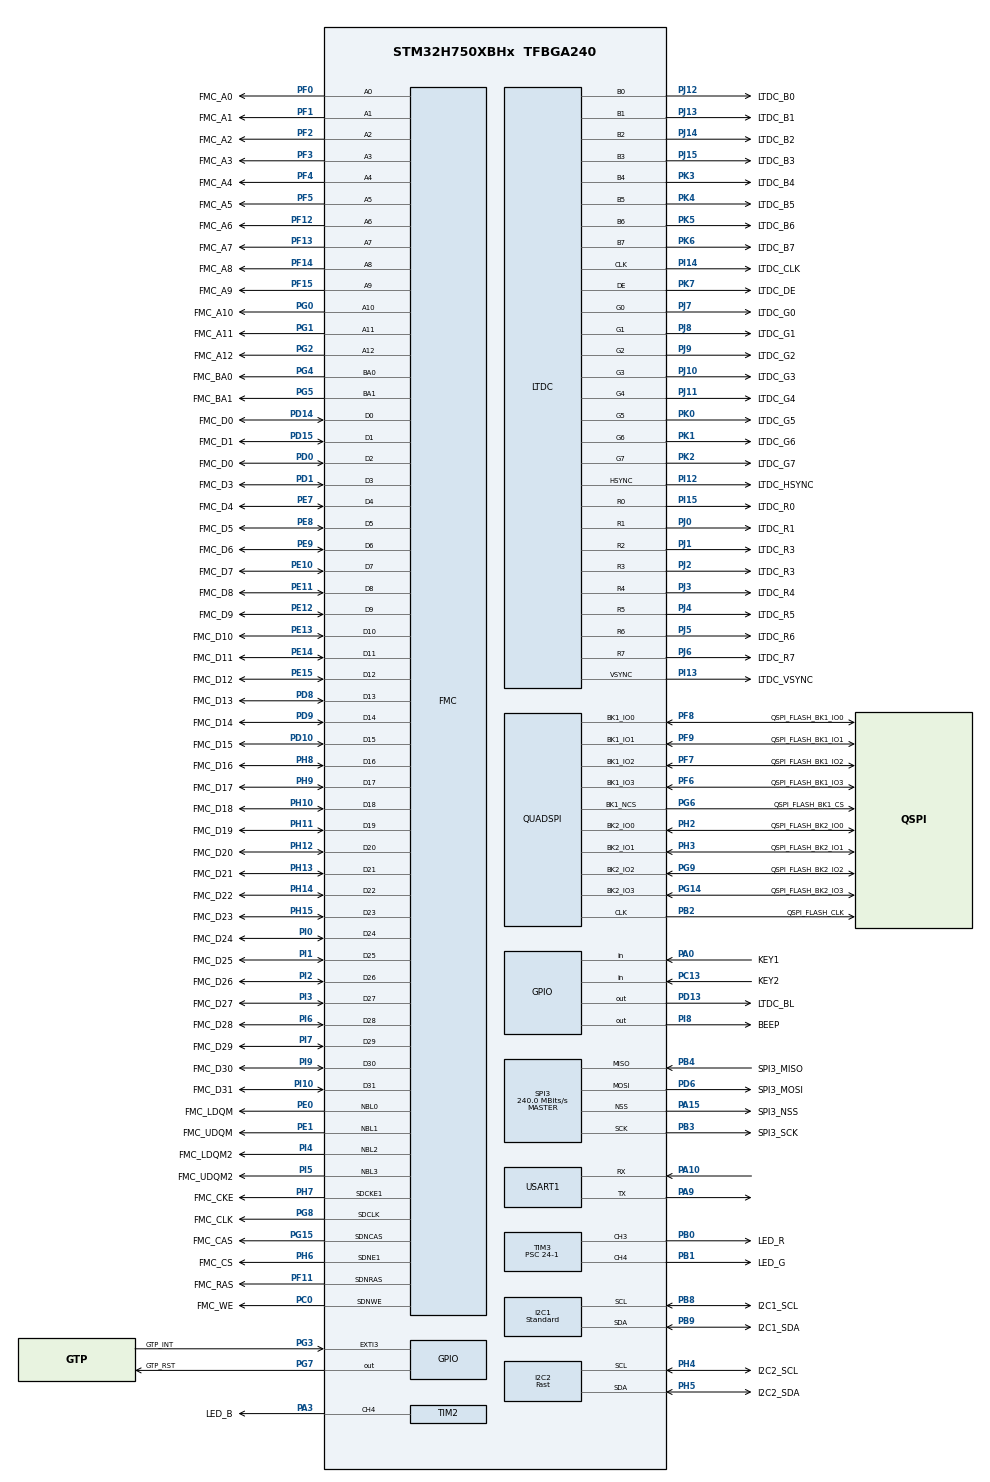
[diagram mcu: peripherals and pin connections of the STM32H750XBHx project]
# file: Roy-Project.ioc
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CORTEX_M7.AccessPermission_S-Cortex_Memory_Protection_Unit_Region1_Settings_S=MPU_REGION_FULL_ACCESS
CORTEX_M7.AccessPermission_S-Cortex_Memory_Protection_Unit_Region2_Settings_S=MPU_REGION_FULL_ACCESS
CORTEX_M7.AccessPermission_S-Cortex_Memory_Protection_Unit_Region3_Settings_S=MPU_REGION_FULL_ACCESS
CORTEX_M7.AccessPermission_S-Cortex_Memory_Protection_Unit_Region4_Settings_S=MPU_REGION_FULL_ACCESS
CORTEX_M7.AccessPermission_S-Cortex_Memory_Protection_Unit_Region5_Settings_S=MPU_REGION_FULL_ACCESS
CORTEX_M7.AccessPermission_S-Cortex_Memory_Protection_Unit_Region6_Settings_S=MPU_REGION_FULL_ACCESS
CORTEX_M7.AccessPermission_Spec=MPU_REGION_FULL_ACCESS
CORTEX_M7.BaseAddress_S-Cortex_Memory_Protection_Unit_Region1_Settings_S=0x30000000
CORTEX_M7.BaseAddress_S-Cortex_Memory_Protection_Unit_Region2_Settings_S=0x30020000
CORTEX_M7.BaseAddress_S-Cortex_Memory_Protection_Unit_Region3_Settings_S=0x30040000
CORTEX_M7.BaseAddress_S-Cortex_Memory_Protection_Unit_Region4_Settings_S=0x38000000
CORTEX_M7.BaseAddress_S-Cortex_Memory_Protection_Unit_Region5_Settings_S=0xD0000000
CORTEX_M7.BaseAddress_S-Cortex_Memory_Protection_Unit_Region6_Settings_S=0x90000000
CORTEX_M7.BaseAddress_Spec=0x24000000
CORTEX_M7.CPU_DCache=Enabled
CORTEX_M7.CPU_ICache=Enabled
CORTEX_M7.DisableExec_Spec=MPU_INSTRUCTION_ACCESS_ENABLE
CORTEX_M7.Enable_S-Cortex_Memory_Protection_Unit_Region1_Settings_S=MPU_REGION_ENABLE
CORTEX_M7.Enable_S-Cortex_Memory_Protection_Unit_Region2_Settings_S=MPU_REGION_ENABLE
CORTEX_M7.Enable_S-Cortex_Memory_Protection_Unit_Region3_Settings_S=MPU_REGION_ENABLE
CORTEX_M7.Enable_S-Cortex_Memory_Protection_Unit_Region4_Settings_S=MPU_REGION_ENABLE
CORTEX_M7.Enable_S-Cortex_Memory_Protection_Unit_Region5_Settings_S=MPU_REGION_ENABLE
CORTEX_M7.Enable_S-Cortex_Memory_Protection_Unit_Region6_Settings_S=MPU_REGION_ENABLE
CORTEX_M7.IsBufferable_Spec=MPU_ACCESS_BUFFERABLE
CORTEX_M7.IsCacheable_S-Cortex_Memory_Protection_Unit_Region1_Settings_S=MPU_ACCESS_CACHEABLE
CORTEX_M7.IsCacheable_S-Cortex_Memory_Protection_Unit_Region2_Settings_S=MPU_ACCESS_CACHEABLE
CORTEX_M7.IsCacheable_S-Cortex_Memory_Protection_Unit_Region3_Settings_S=MPU_ACCESS_CACHEABLE
CORTEX_M7.IsCacheable_S-Cortex_Memory_Protection_Unit_Region4_Settings_S=MPU_ACCESS_CACHEABLE
CORTEX_M7.IsCacheable_S-Cortex_Memory_Protection_Unit_Region5_Settings_S=MPU_ACCESS_CACHEABLE
CORTEX_M7.IsCacheable_S-Cortex_Memory_Protection_Unit_Region6_Settings_S=MPU_ACCESS_CACHEABLE
CORTEX_M7.IsCacheable_Spec=MPU_ACCESS_CACHEABLE
CORTEX_M7.IsShareable_Spec=MPU_ACCESS_NOT_SHAREABLE
CORTEX_M7.Size_S-Cortex_Memory_Protection_Unit_Region1_Settings_S=MPU_REGION_SIZE_128KB
CORTEX_M7.Size_S-Cortex_Memory_Protection_Unit_Region2_Settings_S=MPU_REGION_SIZE_128KB
CORTEX_M7.Size_S-Cortex_Memory_Protection_Unit_Region3_Settings_S=MPU_REGION_SIZE_32KB
CORTEX_M7.Size_S-Cortex_Memory_Protection_Unit_Region4_Settings_S=MPU_REGION_SIZE_64KB
CORTEX_M7.Size_S-Cortex_Memory_Protection_Unit_Region5_Settings_S=MPU_REGION_SIZE_64MB
CORTEX_M7.Size_S-Cortex_Memory_Protection_Unit_Region6_Settings_S=MPU_REGION_SIZE_64MB
CORTEX_M7.Size_Spec=MPU_REGION_SIZE_512KB
CORTEX_M7.SubRegionDisable_S-Cortex_Memory_Protection_Unit_Region1_Settings_S=0x00
CORTEX_M7.SubRegionDisable_S-Cortex_Memory_Protection_Unit_Region2_Settings_S=0x00
CORTEX_M7.SubRegionDisable_S-Cortex_Memory_Protection_Unit_Region3_Settings_S=0x00
CORTEX_M7.SubRegionDisable_S-Cortex_Memory_Protection_Unit_Region4_Settings_S=0x00
CORTEX_M7.SubRegionDisable_S-Cortex_Memory_Protection_Unit_Region5_Settings_S=0x00
CORTEX_M7.SubRegionDisable_S-Cortex_Memory_Protection_Unit_Region6_Settings_S=0x00
CORTEX_M7.SubRegionDisable_Spec=0x00
CORTEX_M7.TypeExtField_Spec=MPU_TEX_LEVEL1
CORTEX_M7.default_mode_Activation=1
DMA2D.ColorMode=DMA2D_OUTPUT_RGB565
DMA2D.Mode=DMA2D_M2M
Dma.I2C1_RX.2.Direction=DMA_PERIPH_TO_MEMORY
Dma.I2C1_RX.2.EventEnable=DISABLE
Dma.I2C1_RX.2.FIFOMode=DMA_FIFOMODE_DISABLE
Dma.I2C1_RX.2.Instance=DMA1_Stream7
Dma.I2C1_RX.2.MemDataAlignment=DMA_MDATAALIGN_BYTE
Dma.I2C1_RX.2.MemInc=DMA_MINC_ENABLE
Dma.I2C1_RX.2.Mode=DMA_NORMAL
Dma.I2C1_RX.2.PeriphDataAlignment=DMA_PDATAALIGN_BYTE
Dma.I2C1_RX.2.PeriphInc=DMA_PINC_DISABLE
Dma.I2C1_RX.2.Polarity=HAL_DMAMUX_REQ_GEN_RISING
Dma.I2C1_RX.2.Priority=DMA_PRIORITY_LOW
Dma.I2C1_RX.2.RequestNumber=1
Dma.I2C1_RX.2.SignalID=NONE
Dma.I2C1_RX.2.SyncEnable=DISABLE
Dma.I2C1_RX.2.SyncPolarity=HAL_DMAMUX_SYNC_NO_EVENT
Dma.I2C1_RX.2.SyncRequestNumber=1
Dma.I2C1_RX.2.SyncSignalID=NONE
Dma.I2C1_TX.1.Direction=DMA_MEMORY_TO_PERIPH
Dma.I2C1_TX.1.EventEnable=DISABLE
Dma.I2C1_TX.1.FIFOMode=DMA_FIFOMODE_DISABLE
Dma.I2C1_TX.1.Instance=DMA1_Stream6
Dma.I2C1_TX.1.MemDataAlignment=DMA_MDATAALIGN_BYTE
Dma.I2C1_TX.1.MemInc=DMA_MINC_ENABLE
Dma.I2C1_TX.1.Mode=DMA_NORMAL
Dma.I2C1_TX.1.PeriphDataAlignment=DMA_PDATAALIGN_BYTE
Dma.I2C1_TX.1.PeriphInc=DMA_PINC_DISABLE
Dma.I2C1_TX.1.Polarity=HAL_DMAMUX_REQ_GEN_RISING
Dma.I2C1_TX.1.Priority=DMA_PRIORITY_LOW
Dma.I2C1_TX.1.RequestNumber=1
Dma.I2C1_TX.1.SignalID=NONE
Dma.I2C1_TX.1.SyncEnable=DISABLE
Dma.I2C1_TX.1.SyncPolarity=HAL_DMAMUX_SYNC_NO_EVENT
Dma.I2C1_TX.1.SyncRequestNumber=1
Dma.I2C1_TX.1.SyncSignalID=NONE
Dma.I2C2_RX.4.Direction=DMA_PERIPH_TO_MEMORY
Dma.I2C2_RX.4.EventEnable=DISABLE
Dma.I2C2_RX.4.FIFOMode=DMA_FIFOMODE_DISABLE
Dma.I2C2_RX.4.Instance=DMA1_Stream4
Dma.I2C2_RX.4.MemDataAlignment=DMA_MDATAALIGN_BYTE
Dma.I2C2_RX.4.MemInc=DMA_MINC_ENABLE
Dma.I2C2_RX.4.Mode=DMA_NORMAL
Dma.I2C2_RX.4.PeriphDataAlignment=DMA_PDATAALIGN_BYTE
Dma.I2C2_RX.4.PeriphInc=DMA_PINC_DISABLE
Dma.I2C2_RX.4.Polarity=HAL_DMAMUX_REQ_GEN_RISING
Dma.I2C2_RX.4.Priority=DMA_PRIORITY_LOW
Dma.I2C2_RX.4.RequestNumber=1
Dma.I2C2_RX.4.SignalID=NONE
Dma.I2C2_RX.4.SyncEnable=DISABLE
Dma.I2C2_RX.4.SyncPolarity=HAL_DMAMUX_SYNC_NO_EVENT
Dma.I2C2_RX.4.SyncRequestNumber=1
Dma.I2C2_RX.4.SyncSignalID=NONE
Dma.I2C2_TX.3.Direction=DMA_MEMORY_TO_PERIPH
Dma.I2C2_TX.3.EventEnable=DISABLE
Dma.I2C2_TX.3.FIFOMode=DMA_FIFOMODE_DISABLE
Dma.I2C2_TX.3.Instance=DMA1_Stream3
Dma.I2C2_TX.3.MemDataAlignment=DMA_MDATAALIGN_BYTE
Dma.I2C2_TX.3.MemInc=DMA_MINC_ENABLE
Dma.I2C2_TX.3.Mode=DMA_NORMAL
Dma.I2C2_TX.3.PeriphDataAlignment=DMA_PDATAALIGN_BYTE
Dma.I2C2_TX.3.PeriphInc=DMA_PINC_DISABLE
Dma.I2C2_TX.3.Polarity=HAL_DMAMUX_REQ_GEN_RISING
Dma.I2C2_TX.3.Priority=DMA_PRIORITY_LOW
Dma.I2C2_TX.3.RequestNumber=1
Dma.I2C2_TX.3.SignalID=NONE
Dma.I2C2_TX.3.SyncEnable=DISABLE
Dma.I2C2_TX.3.SyncPolarity=HAL_DMAMUX_SYNC_NO_EVENT
Dma.I2C2_TX.3.SyncRequestNumber=1
Dma.I2C2_TX.3.SyncSignalID=NONE
Dma.Request0=USART1_RX
Dma.Request1=I2C1_TX
Dma.Request2=I2C1_RX
Dma.Request3=I2C2_TX
Dma.Request4=I2C2_RX
Dma.USART1_RX.0.Direction=DMA_PERIPH_TO_MEMORY
Dma.USART1_RX.0.EventEnable=DISABLE
Dma.USART1_RX.0.FIFOMode=DMA_FIFOMODE_DISABLE
Dma.USART1_RX.0.Instance=DMA1_Stream5
Dma.USART1_RX.0.MemDataAlignment=DMA_MDATAALIGN_BYTE
Dma.USART1_RX.0.MemInc=DMA_MINC_ENABLE
Dma.USART1_RX.0.Mode=DMA_CIRCULAR
Dma.USART1_RX.0.PeriphDataAlignment=DMA_PDATAALIGN_BYTE
Dma.USART1_RX.0.PeriphInc=DMA_PINC_DISABLE
Dma.USART1_RX.0.Polarity=HAL_DMAMUX_REQ_GEN_RISING
Dma.USART1_RX.0.Priority=DMA_PRIORITY_MEDIUM
Dma.USART1_RX.0.RequestNumber=1
Dma.USART1_RX.0.SignalID=NONE
Dma.USART1_RX.0.SyncEnable=DISABLE
Dma.USART1_RX.0.SyncPolarity=HAL_DMAMUX_SYNC_NO_EVENT
Dma.USART1_RX.0.SyncRequestNumber=1
Dma.USART1_RX.0.SyncSignalID=NONE
FMC.CASLatency2=FMC_SDRAM_CAS_LATENCY_3
FMC.ColumnBitsNumber2=FMC_SDRAM_COLUMN_BITS_NUM_9
FMC.ExitSelfRefreshDelay2=9
FMC.LoadToActiveDelay2=2
FMC.RCDDelay2=2
FMC.RPDelay2=2
FMC.ReadPipeDelay2=FMC_SDRAM_RPIPE_DELAY_0
FMC.RowCycleDelay2=8
FMC.SDClockPeriod2=FMC_SDRAM_CLOCK_PERIOD_2
FMC.SelfRefreshTime2=6
FMC.WriteRecoveryTime2=4
I2C1.AddressingMode=I2C_ADDRESSINGMODE_7BIT
I2C1.CustomTiming=Disabled
I2C1.DualAddressMode=I2C_DUALADDRESS_DISABLE
I2C1.I2C_Fall_Time=0
I2C1.I2C_Speed_Mode=I2C_Standard
I2C1.OwnAddress=0
I2C1.Timing=0x307075B1
I2C2.I2C_Speed_Mode=I2C_Fast
I2C2.Timing=0x00B03FDB
LTDC.ActiveW=800
LTDC.Alpha_L0=255
LTDC.FBStartAdress_L0=0xD0000000
LTDC.HBP=46
LTDC.HFP=40
LTDC.HSync=1
LTDC.ImageHeight_L0=480
LTDC.ImageWidth_L0=800
LTDC.Layers=0
LTDC.PixelFormat_L0=LTDC_PIXEL_FORMAT_RGB565
LTDC.VBP=23
LTDC.VFP=13
LTDC.VSync=3
LTDC.WindowX1_L0=800
LTDC.WindowY1_L0=480
Mcu.Family=STM32H7
Mcu.Name=STM32H750XBHx
Mcu.Package=TFBGA240
NVIC.DMA1_Stream3_IRQn=true\:0\:0\:false\:false\:true\:false\:false\:true\:true
NVIC.DMA1_Stream4_IRQn=true\:0\:0\:false\:false\:true\:false\:false\:true\:true
NVIC.DMA1_Stream5_IRQn=true\:2\:0\:true\:false\:true\:false\:false\:true\:true
NVIC.DMA1_Stream6_IRQn=true\:0\:0\:false\:false\:true\:false\:false\:true\:true
NVIC.DMA1_Stream7_IRQn=true\:0\:0\:false\:false\:true\:false\:false\:true\:true
NVIC.DMA2D_IRQn=true\:6\:0\:true\:false\:true\:false\:true\:true\:true
NVIC.EXTI3_IRQn=true\:1\:0\:true\:false\:true\:false\:true\:true\:true
NVIC.I2C1_EV_IRQn=true\:2\:0\:true\:false\:true\:false\:true\:true\:true
NVIC.I2C2_EV_IRQn=true\:0\:0\:false\:false\:true\:false\:true\:true\:true
NVIC.LTDC_IRQn=true\:6\:0\:true\:false\:true\:false\:true\:true\:true
NVIC.PriorityGroup=NVIC_PRIORITYGROUP_4
NVIC.TIM6_DAC_IRQn=true\:15\:0\:false\:false\:true\:false\:false\:true\:true
NVIC.TimeBase=TIM6_DAC_IRQn
NVIC.TimeBaseIP=TIM6
NVIC.USART1_IRQn=true\:2\:0\:true\:false\:true\:false\:true\:true\:true
PA0.GPIO_Label=KEY1
PA0.Signal=GPIO_Input
PA10.GPIO_Speed=GPIO_SPEED_FREQ_VERY_HIGH
PA10.Mode=Asynchronous
PA10.Signal=USART1_RX
PA13\ (JTMS/SWDIO).Mode=Serial_Wire
PA13\ (JTMS/SWDIO).Signal=DEBUG_JTMS-SWDIO
PA14\ (JTCK/SWCLK).Mode=Serial_Wire
PA14\ (JTCK/SWCLK).Signal=DEBUG_JTCK-SWCLK
PA15\ (JTDI).GPIO_Label=SPI3_NSS
PA15\ (JTDI).Mode=NSS_Signal_Hard_Output
PA15\ (JTDI).Signal=SPI3_NSS
PA3.GPIO_Label=LED_B
PA3.GPIO_Speed=GPIO_SPEED_FREQ_VERY_HIGH
PA3.Signal=S_TIM2_CH4
PA9.GPIO_Speed=GPIO_SPEED_FREQ_VERY_HIGH
PA9.Mode=Asynchronous
PA9.Signal=USART1_TX
PB0.GPIO_Label=LED_R
PB0.GPIO_Speed=GPIO_SPEED_FREQ_VERY_HIGH
PB0.Signal=S_TIM3_CH3
PB1.GPIO_Label=LED_G
PB1.GPIO_Speed=GPIO_SPEED_FREQ_VERY_HIGH
PB1.Signal=S_TIM3_CH4
PB2.GPIO_Label=QSPI_FLASH_CLK
PB2.GPIO_Speed=GPIO_SPEED_FREQ_VERY_HIGH
PB2.Mode=Dual_Bank
PB2.Signal=QUADSPI_CLK
PB3\ (JTDO/TRACESWO).GPIO_Label=SPI3_SCK
PB3\ (JTDO/TRACESWO).Mode=Full_Duplex_Master
PB3\ (JTDO/TRACESWO).Signal=SPI3_SCK
PB4\ (NJTRST).GPIO_Label=SPI3_MISO
PB4\ (NJTRST).Mode=Full_Duplex_Master
PB4\ (NJTRST).Signal=SPI3_MISO
PB8.GPIO_Label=I2C1_SCL
PB8.GPIO_Speed=GPIO_SPEED_FREQ_HIGH
PB8.Mode=I2C
PB8.Signal=I2C1_SCL
PB9.GPIO_Label=I2C1_SDA
PB9.GPIO_Speed=GPIO_SPEED_FREQ_HIGH
PB9.Mode=I2C
PB9.Signal=I2C1_SDA
PC0.GPIO_Label=FMC_WE
PC0.GPIO_PuPd=GPIO_PULLUP
PC0.GPIO_Speed_High_Default=GPIO_SPEED_FREQ_HIGH
PC0.Signal=FMC_SDNWE
PC10.GPIO_Label=SDMMC1_D2
PC10.GPIO_Mode=GPIO_MODE_AF_PP
PC10.GPIO_PuPd=GPIO_PULLUP
PC10.GPIO_Speed_High_Default=GPIO_SPEED_FREQ_HIGH
PC10.Signal=SDMMC1_D2
PC11.GPIO_Label=SDMMC1_D3
PC11.GPIO_Mode=GPIO_MODE_AF_PP
PC11.GPIO_PuPd=GPIO_PULLUP
PC11.GPIO_Speed_High_Default=GPIO_SPEED_FREQ_HIGH
PC11.Signal=SDMMC1_D3
PC12.GPIO_Label=SDMMC1_CLK
PC12.GPIO_Mode=GPIO_MODE_AF_PP
PC12.GPIO_PuPd=GPIO_PULLUP
PC12.GPIO_Speed_High_Default=GPIO_SPEED_FREQ_HIGH
PC12.Signal=SDMMC1_CK
PC13.GPIO_Label=KEY2
PC13.Signal=GPIO_Input
PC14-OSC32_IN\ (OSC32_IN).Mode=LSE-External-Oscillator
PC14-OSC32_IN\ (OSC32_IN).Signal=RCC_OSC32_IN
PC15-OSC32_OUT\ (OSC32_OUT).Mode=LSE-External-Oscillator
PC15-OSC32_OUT\ (OSC32_OUT).Signal=RCC_OSC32_OUT
PC8.GPIO_Label=SDMMC1_D0
PC8.GPIO_Mode=GPIO_MODE_AF_PP
PC8.GPIO_PuPd=GPIO_PULLUP
PC8.GPIO_Speed_High_Default=GPIO_SPEED_FREQ_HIGH
PC8.Signal=SDMMC1_D0
PC9.GPIO_Label=SDMMC1_D1
PC9.GPIO_Mode=GPIO_MODE_AF_PP
PC9.GPIO_PuPd=GPIO_PULLUP
PC9.GPIO_Speed_High_Default=GPIO_SPEED_FREQ_HIGH
PC9.Signal=SDMMC1_D1
PD0.GPIO_Label=FMC_D0
PD0.GPIO_PuPd=GPIO_PULLUP
PD0.GPIO_Speed_High_Default=GPIO_SPEED_FREQ_HIGH
PD0.Signal=FMC_D2_DA2
PD1.GPIO_Label=FMC_D3
PD1.GPIO_PuPd=GPIO_PULLUP
PD1.GPIO_Speed_High_Default=GPIO_SPEED_FREQ_HIGH
PD1.Signal=FMC_D3_DA3
PD10.GPIO_Label=FMC_D15
PD10.GPIO_PuPd=GPIO_PULLUP
PD10.GPIO_Speed_High_Default=GPIO_SPEED_FREQ_HIGH
PD10.Signal=FMC_D15_DA15
PD13.GPIO_Label=LTDC_BL
PD13.GPIO_PuPd=GPIO_PULLUP
PD13.GPIO_Speed=GPIO_SPEED_FREQ_MEDIUM
PD13.Signal=GPIO_Output
PD14.GPIO_Label=FMC_D0
PD14.GPIO_PuPd=GPIO_PULLUP
PD14.GPIO_Speed_High_Default=GPIO_SPEED_FREQ_HIGH
PD14.Signal=FMC_D0_DA0
PD15.GPIO_Label=FMC_D1
PD15.GPIO_PuPd=GPIO_PULLUP
PD15.GPIO_Speed_High_Default=GPIO_SPEED_FREQ_HIGH
PD15.Signal=FMC_D1_DA1
PD2.GPIO_Label=SDMMC1_CMD
PD2.GPIO_Mode=GPIO_MODE_AF_PP
PD2.GPIO_PuPd=GPIO_PULLUP
PD2.GPIO_Speed_High_Default=GPIO_SPEED_FREQ_HIGH
PD2.Signal=SDMMC1_CMD
PD6.GPIO_Label=SPI3_MOSI
PD6.Mode=Full_Duplex_Master
PD6.Signal=SPI3_MOSI
PD8.GPIO_Label=FMC_D13
PD8.GPIO_PuPd=GPIO_PULLUP
PD8.GPIO_Speed_High_Default=GPIO_SPEED_FREQ_HIGH
PD8.Signal=FMC_D13_DA13
PD9.GPIO_Label=FMC_D14
PD9.GPIO_PuPd=GPIO_PULLUP
PD9.GPIO_Speed_High_Default=GPIO_SPEED_FREQ_HIGH
PD9.Signal=FMC_D14_DA14
PE0.GPIO_Label=FMC_LDQM
PE0.GPIO_PuPd=GPIO_PULLUP
PE0.GPIO_Speed_High_Default=GPIO_SPEED_FREQ_HIGH
PE0.Signal=FMC_NBL0
PE1.GPIO_Label=FMC_UDQM
PE1.GPIO_PuPd=GPIO_PULLUP
PE1.GPIO_Speed_High_Default=GPIO_SPEED_FREQ_HIGH
PE1.Signal=FMC_NBL1
PE10.GPIO_Label=FMC_D7
PE10.GPIO_PuPd=GPIO_PULLUP
PE10.GPIO_Speed_High_Default=GPIO_SPEED_FREQ_HIGH
PE10.Signal=FMC_D7_DA7
PE11.GPIO_Label=FMC_D8
PE11.GPIO_PuPd=GPIO_PULLUP
PE11.GPIO_Speed_High_Default=GPIO_SPEED_FREQ_HIGH
PE11.Signal=FMC_D8_DA8
PE12.GPIO_Label=FMC_D9
PE12.GPIO_PuPd=GPIO_PULLUP
PE12.GPIO_Speed_High_Default=GPIO_SPEED_FREQ_HIGH
PE12.Signal=FMC_D9_DA9
PE13.GPIO_Label=FMC_D10
PE13.GPIO_PuPd=GPIO_PULLUP
PE13.GPIO_Speed_High_Default=GPIO_SPEED_FREQ_HIGH
PE13.Signal=FMC_D10_DA10
PE14.GPIO_Label=FMC_D11
PE14.GPIO_PuPd=GPIO_PULLUP
PE14.GPIO_Speed_High_Default=GPIO_SPEED_FREQ_HIGH
PE14.Signal=FMC_D11_DA11
PE15.GPIO_Label=FMC_D12
PE15.GPIO_PuPd=GPIO_PULLUP
PE15.GPIO_Speed_High_Default=GPIO_SPEED_FREQ_HIGH
PE15.Signal=FMC_D12_DA12
PE7.GPIO_Label=FMC_D4
PE7.GPIO_PuPd=GPIO_PULLUP
PE7.GPIO_Speed_High_Default=GPIO_SPEED_FREQ_HIGH
PE7.Signal=FMC_D4_DA4
PE8.GPIO_Label=FMC_D5
PE8.GPIO_PuPd=GPIO_PULLUP
PE8.GPIO_Speed_High_Default=GPIO_SPEED_FREQ_HIGH
PE8.Signal=FMC_D5_DA5
PE9.GPIO_Label=FMC_D6
PE9.GPIO_PuPd=GPIO_PULLUP
PE9.GPIO_Speed_High_Default=GPIO_SPEED_FREQ_HIGH
PE9.Signal=FMC_D6_DA6
PF0.GPIO_Label=FMC_A0
PF0.GPIO_PuPd=GPIO_PULLUP
PF0.GPIO_Speed_High_Default=GPIO_SPEED_FREQ_HIGH
PF0.Signal=FMC_A0
PF1.GPIO_Label=FMC_A1
PF1.GPIO_PuPd=GPIO_PULLUP
PF1.GPIO_Speed_High_Default=GPIO_SPEED_FREQ_HIGH
PF1.Signal=FMC_A1
PF11.GPIO_Label=FMC_RAS
PF11.GPIO_PuPd=GPIO_PULLUP
PF11.GPIO_Speed_High_Default=GPIO_SPEED_FREQ_HIGH
PF11.Signal=FMC_SDNRAS
PF12.GPIO_Label=FMC_A6
PF12.GPIO_PuPd=GPIO_PULLUP
PF12.GPIO_Speed_High_Default=GPIO_SPEED_FREQ_HIGH
PF12.Signal=FMC_A6
PF13.GPIO_Label=FMC_A7
PF13.GPIO_PuPd=GPIO_PULLUP
PF13.GPIO_Speed_High_Default=GPIO_SPEED_FREQ_HIGH
PF13.Signal=FMC_A7
PF14.GPIO_Label=FMC_A8
PF14.GPIO_PuPd=GPIO_PULLUP
PF14.GPIO_Speed_High_Default=GPIO_SPEED_FREQ_HIGH
PF14.Signal=FMC_A8
PF15.GPIO_Label=FMC_A9
PF15.GPIO_PuPd=GPIO_PULLUP
PF15.GPIO_Speed_High_Default=GPIO_SPEED_FREQ_HIGH
PF15.Signal=FMC_A9
PF2.GPIO_Label=FMC_A2
PF2.GPIO_PuPd=GPIO_PULLUP
PF2.GPIO_Speed_High_Default=GPIO_SPEED_FREQ_HIGH
PF2.Signal=FMC_A2
PF3.GPIO_Label=FMC_A3
PF3.GPIO_PuPd=GPIO_PULLUP
PF3.GPIO_Speed_High_Default=GPIO_SPEED_FREQ_HIGH
PF3.Signal=FMC_A3
PF4.GPIO_Label=FMC_A4
PF4.GPIO_PuPd=GPIO_PULLUP
PF4.GPIO_Speed_High_Default=GPIO_SPEED_FREQ_HIGH
PF4.Signal=FMC_A4
PF5.GPIO_Label=FMC_A5
PF5.GPIO_PuPd=GPIO_PULLUP
PF5.GPIO_Speed_High_Default=GPIO_SPEED_FREQ_HIGH
PF5.Signal=FMC_A5
PF6.GPIO_Label=QSPI_FLASH_BK1_IO3
PF6.GPIO_Speed=GPIO_SPEED_FREQ_VERY_HIGH
PF6.Mode=Dual_Bank
PF6.Signal=QUADSPI_BK1_IO3
PF7.GPIO_Label=QSPI_FLASH_BK1_IO2
PF7.GPIO_Speed=GPIO_SPEED_FREQ_VERY_HIGH
PF7.Mode=Dual_Bank
PF7.Signal=QUADSPI_BK1_IO2
PF8.GPIO_Label=QSPI_FLASH_BK1_IO0
PF8.GPIO_Speed=GPIO_SPEED_FREQ_VERY_HIGH
PF8.Mode=Dual_Bank
PF8.Signal=QUADSPI_BK1_IO0
PF9.GPIO_Label=QSPI_FLASH_BK1_IO1
PF9.GPIO_Speed=GPIO_SPEED_FREQ_VERY_HIGH
PF9.Mode=Dual_Bank
PF9.Signal=QUADSPI_BK1_IO1
PG0.GPIO_Label=FMC_A10
PG0.GPIO_PuPd=GPIO_PULLUP
PG0.GPIO_Speed_High_Default=GPIO_SPEED_FREQ_HIGH
PG0.Signal=FMC_A10
PG1.GPIO_Label=FMC_A11
PG1.GPIO_PuPd=GPIO_PULLUP
PG1.GPIO_Speed_High_Default=GPIO_SPEED_FREQ_HIGH
PG1.Signal=FMC_A11
PG14.GPIO_Label=QSPI_FLASH_BK2_IO3
PG14.GPIO_Speed=GPIO_SPEED_FREQ_VERY_HIGH
PG14.Mode=Dual_Bank
PG14.Signal=QUADSPI_BK2_IO3
PG15.GPIO_Label=FMC_CAS
PG15.GPIO_PuPd=GPIO_PULLUP
PG15.GPIO_Speed_High_Default=GPIO_SPEED_FREQ_HIGH
PG15.Signal=FMC_SDNCAS
PG2.GPIO_Label=FMC_A12
PG2.GPIO_PuPd=GPIO_PULLUP
PG2.GPIO_Speed_High_Default=GPIO_SPEED_FREQ_HIGH
PG2.Signal=FMC_A12
PG3.GPIO_Label=GTP_INT
PG3.Signal=GPXTI3
PG4.GPIO_Label=FMC_BA0
PG4.GPIO_PuPd=GPIO_PULLUP
PG4.GPIO_Speed_High_Default=GPIO_SPEED_FREQ_HIGH
PG4.Signal=FMC_A14_BA0
PG5.GPIO_Label=FMC_BA1
PG5.GPIO_PuPd=GPIO_PULLUP
PG5.GPIO_Speed_High_Default=GPIO_SPEED_FREQ_HIGH
PG5.Signal=FMC_A15_BA1
PG6.GPIO_Label=QSPI_FLASH_BK1_CS
PG6.GPIO_Speed=GPIO_SPEED_FREQ_VERY_HIGH
PG6.Mode=Enable Chip Select 1 for both banks
PG6.Signal=QUADSPI_BK1_NCS
PG7.GPIO_Label=GTP_RST
PG7.GPIO_PuPd=GPIO_PULLDOWN
PG7.GPIO_Speed=GPIO_SPEED_FREQ_HIGH
PG7.Signal=GPIO_Output
PG8.GPIO_Label=FMC_CLK
PG8.GPIO_PuPd=GPIO_PULLUP
PG8.GPIO_Speed_High_Default=GPIO_SPEED_FREQ_HIGH
PG8.Signal=FMC_SDCLK
PG9.GPIO_Label=QSPI_FLASH_BK2_IO2
PG9.GPIO_Speed=GPIO_SPEED_FREQ_VERY_HIGH
PG9.Mode=Dual_Bank
PG9.Signal=QUADSPI_BK2_IO2
PH0-OSC_IN\ (PH0).Mode=HSE-External-Oscillator
PH0-OSC_IN\ (PH0).Signal=RCC_OSC_IN
PH1-OSC_OUT\ (PH1).Mode=HSE-External-Oscillator
PH1-OSC_OUT\ (PH1).Signal=RCC_OSC_OUT
PH10.GPIO_Label=FMC_D18
PH10.GPIO_PuPd=GPIO_PULLUP
PH10.GPIO_Speed_High_Default=GPIO_SPEED_FREQ_HIGH
PH10.Signal=FMC_D18
PH11.GPIO_Label=FMC_D19
PH11.GPIO_PuPd=GPIO_PULLUP
PH11.GPIO_Speed_High_Default=GPIO_SPEED_FREQ_HIGH
PH11.Signal=FMC_D19
PH12.GPIO_Label=FMC_D20
PH12.GPIO_PuPd=GPIO_PULLUP
PH12.GPIO_Speed_High_Default=GPIO_SPEED_FREQ_HIGH
PH12.Signal=FMC_D20
PH13.GPIO_Label=FMC_D21
PH13.GPIO_PuPd=GPIO_PULLUP
PH13.GPIO_Speed_High_Default=GPIO_SPEED_FREQ_HIGH
PH13.Signal=FMC_D21
PH14.GPIO_Label=FMC_D22
PH14.GPIO_PuPd=GPIO_PULLUP
PH14.GPIO_Speed_High_Default=GPIO_SPEED_FREQ_HIGH
PH14.Signal=FMC_D22
PH15.GPIO_Label=FMC_D23
PH15.GPIO_PuPd=GPIO_PULLUP
PH15.GPIO_Speed_High_Default=GPIO_SPEED_FREQ_HIGH
PH15.Signal=FMC_D23
PH2.GPIO_Label=QSPI_FLASH_BK2_IO0
PH2.GPIO_Speed=GPIO_SPEED_FREQ_VERY_HIGH
PH2.Mode=Dual_Bank
PH2.Signal=QUADSPI_BK2_IO0
PH3.GPIO_Label=QSPI_FLASH_BK2_IO1
PH3.GPIO_Speed=GPIO_SPEED_FREQ_VERY_HIGH
PH3.Mode=Dual_Bank
PH3.Signal=QUADSPI_BK2_IO1
PH4.GPIO_Label=I2C2_SCL
PH4.GPIO_Speed=GPIO_SPEED_FREQ_HIGH
PH4.Mode=I2C
PH4.Signal=I2C2_SCL
PH5.GPIO_Label=I2C2_SDA
PH5.GPIO_Speed=GPIO_SPEED_FREQ_HIGH
PH5.Mode=I2C
PH5.Signal=I2C2_SDA
PH6.GPIO_Label=FMC_CS
PH6.GPIO_PuPd=GPIO_PULLUP
PH6.GPIO_Speed_High_Default=GPIO_SPEED_FREQ_HIGH
PH6.Mode=SdramChipSelect2_2
PH6.Signal=FMC_SDNE1
PH7.GPIO_Label=FMC_CKE
PH7.GPIO_PuPd=GPIO_PULLUP
PH7.GPIO_Speed_High_Default=GPIO_SPEED_FREQ_HIGH
PH7.Mode=SdramChipSelect2_2
PH7.Signal=FMC_SDCKE1
PH8.GPIO_Label=FMC_D16
PH8.GPIO_PuPd=GPIO_PULLUP
PH8.GPIO_Speed_High_Default=GPIO_SPEED_FREQ_HIGH
PH8.Signal=FMC_D16
PH9.GPIO_Label=FMC_D17
PH9.GPIO_PuPd=GPIO_PULLUP
PH9.GPIO_Speed_High_Default=GPIO_SPEED_FREQ_HIGH
PH9.Signal=FMC_D17
PI0.GPIO_Label=FMC_D24
PI0.GPIO_PuPd=GPIO_PULLUP
PI0.GPIO_Speed_High_Default=GPIO_SPEED_FREQ_HIGH
PI0.Signal=FMC_D24
PI1.GPIO_Label=FMC_D25
PI1.GPIO_PuPd=GPIO_PULLUP
PI1.GPIO_Speed_High_Default=GPIO_SPEED_FREQ_HIGH
PI1.Signal=FMC_D25
PI10.GPIO_Label=FMC_D31
PI10.GPIO_PuPd=GPIO_PULLUP
PI10.GPIO_Speed_High_Default=GPIO_SPEED_FREQ_HIGH
PI10.Signal=FMC_D31
PI12.GPIO_Label=LTDC_HSYNC
PI12.GPIO_Mode=GPIO_MODE_AF_PP
PI12.GPIO_PuPd=GPIO_PULLUP
PI12.GPIO_Speed=GPIO_SPEED_FREQ_HIGH
PI12.Mode=RGB888
PI12.Signal=LTDC_HSYNC
PI13.GPIO_Label=LTDC_VSYNC
PI13.GPIO_Mode=GPIO_MODE_AF_PP
PI13.GPIO_PuPd=GPIO_PULLUP
PI13.GPIO_Speed=GPIO_SPEED_FREQ_HIGH
PI13.Mode=RGB888
PI13.Signal=LTDC_VSYNC
PI14.GPIO_Label=LTDC_CLK
PI14.GPIO_Mode=GPIO_MODE_AF_PP
PI14.GPIO_PuPd=GPIO_PULLUP
PI14.GPIO_Speed=GPIO_SPEED_FREQ_HIGH
PI14.Mode=RGB888
PI14.Signal=LTDC_CLK
PI15.GPIO_Label=LTDC_R0
PI15.GPIO_Mode=GPIO_MODE_AF_PP
PI15.GPIO_PuPd=GPIO_PULLUP
PI15.GPIO_Speed=GPIO_SPEED_FREQ_HIGH
PI15.Mode=RGB888
PI15.Signal=LTDC_R0
PI2.GPIO_Label=FMC_D26
PI2.GPIO_PuPd=GPIO_PULLUP
PI2.GPIO_Speed_High_Default=GPIO_SPEED_FREQ_HIGH
PI2.Signal=FMC_D26
PI3.GPIO_Label=FMC_D27
PI3.GPIO_PuPd=GPIO_PULLUP
PI3.GPIO_Speed_High_Default=GPIO_SPEED_FREQ_HIGH
PI3.Signal=FMC_D27
PI4.GPIO_Label=FMC_LDQM2
PI4.GPIO_PuPd=GPIO_PULLUP
PI4.GPIO_Speed_High_Default=GPIO_SPEED_FREQ_HIGH
PI4.Signal=FMC_NBL2
PI5.GPIO_Label=FMC_UDQM2
PI5.GPIO_PuPd=GPIO_PULLUP
PI5.GPIO_Speed_High_Default=GPIO_SPEED_FREQ_HIGH
PI5.Signal=FMC_NBL3
PI6.GPIO_Label=FMC_D28
PI6.GPIO_PuPd=GPIO_PULLUP
PI6.GPIO_Speed_High_Default=GPIO_SPEED_FREQ_HIGH
PI6.Signal=FMC_D28
PI7.GPIO_Label=FMC_D29
PI7.GPIO_PuPd=GPIO_PULLUP
PI7.GPIO_Speed_High_Default=GPIO_SPEED_FREQ_HIGH
PI7.Signal=FMC_D29
PI8.GPIO_Label=BEEP
PI8.Signal=GPIO_Output
PI9.GPIO_Label=FMC_D30
PI9.GPIO_PuPd=GPIO_PULLUP
PI9.GPIO_Speed_High_Default=GPIO_SPEED_FREQ_HIGH
PI9.Signal=FMC_D30
PJ0.GPIO_Label=LTDC_R1
PJ0.GPIO_Mode=GPIO_MODE_AF_PP
PJ0.GPIO_PuPd=GPIO_PULLUP
PJ0.GPIO_Speed=GPIO_SPEED_FREQ_HIGH
PJ0.Mode=RGB888
PJ0.Signal=LTDC_R1
PJ1.GPIO_Label=LTDC_R3
PJ1.Mode=RGB888
PJ1.Signal=LTDC_R2
PJ10.GPIO_Label=LTDC_G3
PJ10.GPIO_Mode=GPIO_MODE_AF_PP
PJ10.GPIO_PuPd=GPIO_PULLUP
PJ10.GPIO_Speed=GPIO_SPEED_FREQ_HIGH
PJ10.Mode=RGB888
PJ10.Signal=LTDC_G3
PJ11.GPIO_Label=LTDC_G4
PJ11.GPIO_Mode=GPIO_MODE_AF_PP
PJ11.GPIO_PuPd=GPIO_PULLUP
PJ11.GPIO_Speed=GPIO_SPEED_FREQ_HIGH
PJ11.Mode=RGB888
PJ11.Signal=LTDC_G4
PJ12.GPIO_Label=LTDC_B0
PJ12.GPIO_Mode=GPIO_MODE_AF_PP
PJ12.GPIO_PuPd=GPIO_PULLUP
PJ12.GPIO_Speed=GPIO_SPEED_FREQ_HIGH
PJ12.Mode=RGB888
PJ12.Signal=LTDC_B0
PJ13.GPIO_Label=LTDC_B1
PJ13.GPIO_Mode=GPIO_MODE_AF_PP
PJ13.GPIO_PuPd=GPIO_PULLUP
PJ13.GPIO_Speed=GPIO_SPEED_FREQ_HIGH
PJ13.Mode=RGB888
PJ13.Signal=LTDC_B1
PJ14.GPIO_Label=LTDC_B2
PJ14.GPIO_Mode=GPIO_MODE_AF_PP
PJ14.GPIO_PuPd=GPIO_PULLUP
PJ14.GPIO_Speed=GPIO_SPEED_FREQ_HIGH
PJ14.Mode=RGB888
PJ14.Signal=LTDC_B2
PJ15.GPIO_Label=LTDC_B3
PJ15.GPIO_Mode=GPIO_MODE_AF_PP
PJ15.GPIO_PuPd=GPIO_PULLUP
PJ15.GPIO_Speed=GPIO_SPEED_FREQ_HIGH
PJ15.Mode=RGB888
PJ15.Signal=LTDC_B3
PJ2.GPIO_Label=LTDC_R3
PJ2.GPIO_Mode=GPIO_MODE_AF_PP
PJ2.GPIO_PuPd=GPIO_PULLUP
PJ2.GPIO_Speed=GPIO_SPEED_FREQ_HIGH
PJ2.Mode=RGB888
PJ2.Signal=LTDC_R3
PJ3.GPIO_Label=LTDC_R4
PJ3.GPIO_Mode=GPIO_MODE_AF_PP
PJ3.GPIO_PuPd=GPIO_PULLUP
PJ3.GPIO_Speed=GPIO_SPEED_FREQ_HIGH
PJ3.Mode=RGB888
PJ3.Signal=LTDC_R4
PJ4.GPIO_Label=LTDC_R5
PJ4.GPIO_Mode=GPIO_MODE_AF_PP
PJ4.GPIO_PuPd=GPIO_PULLUP
PJ4.GPIO_Speed=GPIO_SPEED_FREQ_HIGH
PJ4.Mode=RGB888
PJ4.Signal=LTDC_R5
PJ5.GPIO_Label=LTDC_R6
PJ5.GPIO_Mode=GPIO_MODE_AF_PP
PJ5.GPIO_PuPd=GPIO_PULLUP
PJ5.GPIO_Speed=GPIO_SPEED_FREQ_HIGH
PJ5.Mode=RGB888
PJ5.Signal=LTDC_R6
PJ6.GPIO_Label=LTDC_R7
PJ6.GPIO_Mode=GPIO_MODE_AF_PP
PJ6.GPIO_PuPd=GPIO_PULLUP
PJ6.GPIO_Speed=GPIO_SPEED_FREQ_HIGH
PJ6.Mode=RGB888
PJ6.Signal=LTDC_R7
PJ7.GPIO_Label=LTDC_G0
PJ7.GPIO_Mode=GPIO_MODE_AF_PP
PJ7.GPIO_PuPd=GPIO_PULLUP
PJ7.GPIO_Speed=GPIO_SPEED_FREQ_HIGH
PJ7.Mode=RGB888
PJ7.Signal=LTDC_G0
PJ8.GPIO_Label=LTDC_G1
PJ8.GPIO_Mode=GPIO_MODE_AF_PP
PJ8.GPIO_PuPd=GPIO_PULLUP
PJ8.GPIO_Speed=GPIO_SPEED_FREQ_HIGH
PJ8.Mode=RGB888
PJ8.Signal=LTDC_G1
PJ9.GPIO_Label=LTDC_G2
PJ9.GPIO_Mode=GPIO_MODE_AF_PP
PJ9.GPIO_PuPd=GPIO_PULLUP
PJ9.GPIO_Speed=GPIO_SPEED_FREQ_HIGH
PJ9.Mode=RGB888
PJ9.Signal=LTDC_G2
PK0.GPIO_Label=LTDC_G5
PK0.GPIO_Mode=GPIO_MODE_AF_PP
PK0.GPIO_PuPd=GPIO_PULLUP
PK0.GPIO_Speed=GPIO_SPEED_FREQ_HIGH
PK0.Mode=RGB888
PK0.Signal=LTDC_G5
PK1.GPIO_Label=LTDC_G6
PK1.GPIO_Mode=GPIO_MODE_AF_PP
PK1.GPIO_PuPd=GPIO_PULLUP
PK1.GPIO_Speed=GPIO_SPEED_FREQ_HIGH
PK1.Mode=RGB888
PK1.Signal=LTDC_G6
PK2.GPIO_Label=LTDC_G7
PK2.GPIO_Mode=GPIO_MODE_AF_PP
PK2.GPIO_PuPd=GPIO_PULLUP
PK2.GPIO_Speed=GPIO_SPEED_FREQ_HIGH
PK2.Mode=RGB888
PK2.Signal=LTDC_G7
PK3.GPIO_Label=LTDC_B4
PK3.GPIO_Mode=GPIO_MODE_AF_PP
PK3.GPIO_PuPd=GPIO_PULLUP
PK3.GPIO_Speed=GPIO_SPEED_FREQ_HIGH
PK3.Mode=RGB888
PK3.Signal=LTDC_B4
PK4.GPIO_Label=LTDC_B5
PK4.GPIO_Mode=GPIO_MODE_AF_PP
PK4.GPIO_PuPd=GPIO_PULLUP
PK4.GPIO_Speed=GPIO_SPEED_FREQ_HIGH
PK4.Mode=RGB888
PK4.Signal=LTDC_B5
PK5.GPIO_Label=LTDC_B6
PK5.GPIO_Mode=GPIO_MODE_AF_PP
PK5.GPIO_PuPd=GPIO_PULLUP
PK5.GPIO_Speed=GPIO_SPEED_FREQ_HIGH
PK5.Mode=RGB888
PK5.Signal=LTDC_B6
PK6.GPIO_Label=LTDC_B7
PK6.GPIO_Mode=GPIO_MODE_AF_PP
PK6.GPIO_PuPd=GPIO_PULLUP
PK6.GPIO_Speed=GPIO_SPEED_FREQ_HIGH
PK6.Mode=RGB888
PK6.Signal=LTDC_B7
PK7.GPIO_Label=LTDC_DE
PK7.GPIO_Mode=GPIO_MODE_AF_PP
PK7.GPIO_PuPd=GPIO_PULLUP
PK7.GPIO_Speed=GPIO_SPEED_FREQ_HIGH
PK7.Mode=RGB888
PK7.Signal=LTDC_DE
ProjectManager.HeapSize=0x400
ProjectManager.StackSize=0x1000
ProjectManager.TargetToolchain=MDK-ARM V5.32
QUADSPI.ChipSelectHighTime=QSPI_CS_HIGH_TIME_3_CYCLE
QUADSPI.ClockPrescaler=1
QUADSPI.FifoThreshold=32
QUADSPI.FlashSize=26-1
QUADSPI.SampleShifting=QSPI_SAMPLE_SHIFTING_HALFCYCLE
RCC.ADCFreq_Value=200000000
RCC.APB1Freq_Value=120000000
RCC.APB2Freq_Value=120000000
RCC.APB3Freq_Value=120000000
RCC.APB4Freq_Value=120000000
RCC.CortexFreq_Value=480000000
RCC.D1PPRE=RCC_APB3_DIV2
RCC.D2PPRE1=RCC_APB1_DIV2
RCC.D2PPRE2=RCC_APB2_DIV2
RCC.D3PPRE=RCC_APB4_DIV2
RCC.DIVM1=5
RCC.DIVM2=2
RCC.DIVM3=1
RCC.DIVN1=192
RCC.DIVN2=16
RCC.DIVN3=6
RCC.DIVP2=1
RCC.DIVR3=6
RCC.EnbaleCSS=true
RCC.HCLKFreq_Value=240000000
RCC.HPRE=RCC_HCLK_DIV2
RCC.PLL2FRACN=0
RCC.PLL3FRACN=0
RCC.PLLFRACN=0
RCC.PLLSourceVirtual=RCC_PLLSOURCE_HSE
RCC.RTCClockSelection=RCC_RTCCLKSOURCE_LSE
RCC.SDMMC1CLockSelection=RCC_SDMMCCLKSOURCE_PLL2
RCC.SPI123CLockSelection=RCC_SPI123CLKSOURCE_PLL2
RCC.SYSCLKFreq_VALUE=480000000
RCC.SYSCLKSource=RCC_SYSCLKSOURCE_PLLCLK
RCC.USBFreq_Value=480000000
RTC.Date=27
RTC.Format=RTC_FORMAT_BIN
RTC.Hours=13
RTC.Minutes=10
RTC.Month=RTC_MONTH_AUGUST
RTC.WeekDay=RTC_WEEKDAY_SATURDAY
RTC.Year=22
SH.FMC_A0.0=FMC_A0,13b-sda2
SH.FMC_A1.0=FMC_A1,13b-sda2
SH.FMC_A10.0=FMC_A10,13b-sda2
SH.FMC_A11.0=FMC_A11,13b-sda2
SH.FMC_A12.0=FMC_A12,13b-sda2
SH.FMC_A14_BA0.0=FMC_BA0,FourSdramBanks2
SH.FMC_A15_BA1.0=FMC_BA1,FourSdramBanks2
SH.FMC_A2.0=FMC_A2,13b-sda2
SH.FMC_A3.0=FMC_A3,13b-sda2
SH.FMC_A4.0=FMC_A4,13b-sda2
SH.FMC_A5.0=FMC_A5,13b-sda2
SH.FMC_A6.0=FMC_A6,13b-sda2
SH.FMC_A7.0=FMC_A7,13b-sda2
SH.FMC_A8.0=FMC_A8,13b-sda2
SH.FMC_A9.0=FMC_A9,13b-sda2
SH.FMC_D0_DA0.0=FMC_D0,sd-32b-d2
SH.FMC_D10_DA10.0=FMC_D10,sd-32b-d2
SH.FMC_D11_DA11.0=FMC_D11,sd-32b-d2
SH.FMC_D12_DA12.0=FMC_D12,sd-32b-d2
SH.FMC_D13_DA13.0=FMC_D13,sd-32b-d2
SH.FMC_D14_DA14.0=FMC_D14,sd-32b-d2
SH.FMC_D15_DA15.0=FMC_D15,sd-32b-d2
SH.FMC_D16.0=FMC_D16,sd-32b-d2
SH.FMC_D17.0=FMC_D17,sd-32b-d2
SH.FMC_D18.0=FMC_D18,sd-32b-d2
SH.FMC_D19.0=FMC_D19,sd-32b-d2
SH.FMC_D1_DA1.0=FMC_D1,sd-32b-d2
SH.FMC_D20.0=FMC_D20,sd-32b-d2
SH.FMC_D21.0=FMC_D21,sd-32b-d2
SH.FMC_D22.0=FMC_D22,sd-32b-d2
SH.FMC_D23.0=FMC_D23,sd-32b-d2
SH.FMC_D24.0=FMC_D24,sd-32b-d2
SH.FMC_D25.0=FMC_D25,sd-32b-d2
SH.FMC_D26.0=FMC_D26,sd-32b-d2
SH.FMC_D27.0=FMC_D27,sd-32b-d2
SH.FMC_D28.0=FMC_D28,sd-32b-d2
SH.FMC_D29.0=FMC_D29,sd-32b-d2
SH.FMC_D2_DA2.0=FMC_D2,sd-32b-d2
SH.FMC_D30.0=FMC_D30,sd-32b-d2
SH.FMC_D31.0=FMC_D31,sd-32b-d2
SH.FMC_D3_DA3.0=FMC_D3,sd-32b-d2
SH.FMC_D4_DA4.0=FMC_D4,sd-32b-d2
SH.FMC_D5_DA5.0=FMC_D5,sd-32b-d2
SH.FMC_D6_DA6.0=FMC_D6,sd-32b-d2
SH.FMC_D7_DA7.0=FMC_D7,sd-32b-d2
SH.FMC_D8_DA8.0=FMC_D8,sd-32b-d2
SH.FMC_D9_DA9.0=FMC_D9,sd-32b-d2
SH.FMC_NBL0.0=FMC_NBL0,Sd4ByteEnable2
SH.FMC_NBL1.0=FMC_NBL1,Sd4ByteEnable2
SH.FMC_NBL2.0=FMC_NBL2,Sd4ByteEnable2
SH.FMC_NBL3.0=FMC_NBL3,Sd4ByteEnable2
SH.FMC_SDCLK.0=FMC_SDCLK,13b-sda2
SH.FMC_SDNCAS.0=FMC_SDNCAS,13b-sda2
SH.FMC_SDNRAS.0=FMC_SDNRAS,13b-sda2
SH.FMC_SDNWE.0=FMC_SDNWE,13b-sda2
SH.S_TIM2_CH4.0=TIM2_CH4,PWM Generation4 CH4
SH.S_TIM3_CH3.0=TIM3_CH3,PWM Generation3 CH3
SH.S_TIM3_CH4.0=TIM3_CH4,PWM Generation4 CH4
SPI3.BaudRatePrescaler=SPI_BAUDRATEPRESCALER_2
<<<<<<< HEAD
SPI3.CLKPolarity=SPI_POLARITY_LOW
SPI3.CalculateBaudRate=100.0 MBits/s
SPI3.Direction=SPI_DIRECTION_2LINES
=======
SPI3.CalculateBaudRate=240.0 MBits/s
SPI3.Direction=SPI_DIRECTION_2LINES
>>>>>>> 44ace04 (1.新增 SPI3 IO 配置)
SPI3.Mode=SPI_MODE_MASTER
SPI3.VirtualNSS=VM_NSSHARD
SPI3.VirtualType=VM_MASTER
STMicroelectronics.X-CUBE-AZRTOS-H7.2.1.0.TX_APP_MEM_POOL_SIZE=64*1024
STMicroelectronics.X-CUBE-AZRTOS-H7.2.1.0.TX_BLOCK_POOL_ENABLE_PERFORMANCE_INFO=1
STMicroelectronics.X-CUBE-AZRTOS-H7.2.1.0.TX_BYTE_POOL_ENABLE_PERFORMANCE_INFO=1
STMicroelectronics.X-CUBE-AZRTOS-H7.2.1.0.TX_ENABLE_EXECUTION_CHANGE_NOTIFY=1
STMicroelectronics.X-CUBE-AZRTOS-H7.2.1.0.TX_ENABLE_STACK_CHECKING=1
STMicroelectronics.X-CUBE-AZRTOS-H7.2.1.0.TX_EVENT_FLAGS_ENABLE_PERFORMANCE_INFO=1
STMicroelectronics.X-CUBE-AZRTOS-H7.2.1.0.TX_INLINE_THREAD_RESUME_SUSPEND=1
STMicroelectronics.X-CUBE-AZRTOS-H7.2.1.0.TX_MUTEX_ENABLE_PERFORMANCE_INFO=1
STMicroelectronics.X-CUBE-AZRTOS-H7.2.1.0.TX_QUEUE_ENABLE_PERFORMANCE_INFO=1
STMicroelectronics.X-CUBE-AZRTOS-H7.2.1.0.TX_TIMER_TICKS_PER_SECOND=1000
STMicroelectronics.X-CUBE-AZRTOS-H7.2.1.0.ThreadXCcRTOSJjThreadXJjCore=true
STMicroelectronics.X-CUBE-AZRTOS-H7.2.1.0.ThreadXCcRTOSJjThreadXJjPerformanceInfo=true
STMicroelectronics.X-CUBE-AZRTOS-H7.2.1.0.ThreadXCcRTOSJjThreadXJjTraceXOosupport=true
STMicroelectronics.X-CUBE-AZRTOS-H7.2.1.0_IsAnAzureRtosMw=true
STMicroelectronics.X-CUBE-TOUCHGFX.4.20.0_IsPackSelfContextualization=true
TIM2.Channel-PWM\ Generation4\ CH4=TIM_CHANNEL_4
TIM2.OCPolarity_4=TIM_OCPOLARITY_LOW
TIM2.Period=10000-1
TIM2.Prescaler=24-1
TIM3.Channel-PWM\ Generation3\ CH3=TIM_CHANNEL_3
TIM3.Channel-PWM\ Generation4\ CH4=TIM_CHANNEL_4
TIM3.OCPolarity_3=TIM_OCPOLARITY_LOW
TIM3.OCPolarity_4=TIM_OCPOLARITY_LOW
TIM3.Period=10000-1
TIM3.Prescaler=24-1
USART1.VirtualMode-Asynchronous=VM_ASYNC
VP_DMA2D_VS_DMA2D.Mode=DMA2D_Activate
VP_RTC_VS_RTC_Activate.Mode=RTC_Enabled
VP_RTC_VS_RTC_Calendar.Mode=RTC_Calendar
VP_STMicroelectronics.X-CUBE-AZRTOS-H7_VS_RTOSJjThreadX_6.1.10_2.1.0.Mode=RTOSJjThreadX
VP_SYS_VS_tim6.Mode=TIM6
board=custom

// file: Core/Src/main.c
/* USER CODE BEGIN Header */
/**
 ******************************************************************************
 * @file           : main.c
 * @brief          : Main program body
 ******************************************************************************
 * @attention
 *
 * Copyright (c) 2022 STMicroelectronics.
 * All rights reserved.
 *
 * This software is licensed under terms that can be found in the LICENSE file
 * in the root directory of this software component.
 * If no LICENSE file comes with this software, it is provided AS-IS.
 *
 ******************************************************************************
 */
/* USER CODE END Header */
#include "main.h"
#include "app_threadx.h"
#include "dma.h"
#include "dma2d.h"
#include "i2c.h"
#include "ltdc.h"
#include "quadspi.h"
#include "rtc.h"
#include "spi.h"
#include "tim.h"
#include "usart.h"
#include "gpio.h"
#include "fmc.h"

void SystemClock_Config(void);
static void MPU_Config(void);
/* USER CODE BEGIN PFP */
extern void MainAPP(void);
/* USER CODE END PFP */

int main(void)
{
  /* USER CODE BEGIN 1 */
  uint32_t *SouceAddr = (uint32_t *)QSPI_BASE;
  uint32_t *DestAddr = (uint32_t *)D1_DTCMRAM_BASE;
  memcpy(DestAddr, SouceAddr, 0x400);
  SCB->VTOR = D1_DTCMRAM_BASE;

  /* USER CODE END 1 */

  /* MPU Configuration--------------------------------------------------------*/
  MPU_Config();

  /* Enable I-Cache---------------------------------------------------------*/
  SCB_EnableICache();

  /* Enable D-Cache---------------------------------------------------------*/
  SCB_EnableDCache();

  /* MCU Configuration--------------------------------------------------------*/

  /* Reset of all peripherals, Initializes the Flash interface and the Systick. */
  HAL_Init();

  /* Configure the system clock */
  SystemClock_Config();

  /* Initialize all configured peripherals */
  MX_GPIO_Init();
  MX_DMA_Init();
  MX_USART1_UART_Init();
  MX_TIM2_Init();
  MX_TIM3_Init();
  MX_FMC_Init();
  MX_QUADSPI_Init();
  MX_I2C1_Init();
  MX_DMA2D_Init();
  MX_LTDC_Init();
  MX_I2C2_Init();
  MX_RTC_Init();
  MX_SPI3_Init();
  /* USER CODE BEGIN 2 */
  MainAPP();
#if 0
  /* USER CODE END 2 */

  MX_ThreadX_Init();

  /* We should never get here as control is now taken by the scheduler */
  /* Infinite loop */
  while (1)
  {

    /* USER CODE BEGIN 3 */
  }
#endif
  /* USER CODE END 3 */
}

void SystemClock_Config(void)
{
  RCC_OscInitTypeDef RCC_OscInitStruct = {0};
  RCC_ClkInitTypeDef RCC_ClkInitStruct = {0};

  /** Supply configuration update enable
  */
  HAL_PWREx_ConfigSupply(PWR_LDO_SUPPLY);

  /** Configure the main internal regulator output voltage
  */
  __HAL_PWR_VOLTAGESCALING_CONFIG(PWR_REGULATOR_VOLTAGE_SCALE1);

  while(!__HAL_PWR_GET_FLAG(PWR_FLAG_VOSRDY)) {}

  __HAL_RCC_SYSCFG_CLK_ENABLE();
  __HAL_PWR_VOLTAGESCALING_CONFIG(PWR_REGULATOR_VOLTAGE_SCALE0);

  while(!__HAL_PWR_GET_FLAG(PWR_FLAG_VOSRDY)) {}

  /** Configure LSE Drive Capability
  */
  HAL_PWR_EnableBkUpAccess();
  __HAL_RCC_LSEDRIVE_CONFIG(RCC_LSEDRIVE_LOW);

  /** Macro to configure the PLL clock source
  */
  __HAL_RCC_PLL_PLLSOURCE_CONFIG(RCC_PLLSOURCE_HSE);

  /** Initializes the RCC Oscillators according to the specified parameters
  * in the RCC_OscInitTypeDef structure.
  */
  RCC_OscInitStruct.OscillatorType = RCC_OSCILLATORTYPE_HSE|RCC_OSCILLATORTYPE_LSE;
  RCC_OscInitStruct.HSEState = RCC_HSE_ON;
  RCC_OscInitStruct.LSEState = RCC_LSE_ON;
  RCC_OscInitStruct.PLL.PLLState = RCC_PLL_ON;
  RCC_OscInitStruct.PLL.PLLSource = RCC_PLLSOURCE_HSE;
  RCC_OscInitStruct.PLL.PLLM = 5;
  RCC_OscInitStruct.PLL.PLLN = 192;
  RCC_OscInitStruct.PLL.PLLP = 2;
  RCC_OscInitStruct.PLL.PLLQ = 2;
  RCC_OscInitStruct.PLL.PLLR = 2;
  RCC_OscInitStruct.PLL.PLLRGE = RCC_PLL1VCIRANGE_2;
  RCC_OscInitStruct.PLL.PLLVCOSEL = RCC_PLL1VCOWIDE;
  RCC_OscInitStruct.PLL.PLLFRACN = 0;
  if (HAL_RCC_OscConfig(&RCC_OscInitStruct) != HAL_OK)
  {
    Error_Handler();
  }

  /** Initializes the CPU, AHB and APB buses clocks
  */
  RCC_ClkInitStruct.ClockType = RCC_CLOCKTYPE_HCLK|RCC_CLOCKTYPE_SYSCLK
                              |RCC_CLOCKTYPE_PCLK1|RCC_CLOCKTYPE_PCLK2
                              |RCC_CLOCKTYPE_D3PCLK1|RCC_CLOCKTYPE_D1PCLK1;
  RCC_ClkInitStruct.SYSCLKSource = RCC_SYSCLKSOURCE_PLLCLK;
  RCC_ClkInitStruct.SYSCLKDivider = RCC_SYSCLK_DIV1;
  RCC_ClkInitStruct.AHBCLKDivider = RCC_HCLK_DIV2;
  RCC_ClkInitStruct.APB3CLKDivider = RCC_APB3_DIV2;
  RCC_ClkInitStruct.APB1CLKDivider = RCC_APB1_DIV2;
  RCC_ClkInitStruct.APB2CLKDivider = RCC_APB2_DIV2;
  RCC_ClkInitStruct.APB4CLKDivider = RCC_APB4_DIV2;

  if (HAL_RCC_ClockConfig(&RCC_ClkInitStruct, FLASH_LATENCY_4) != HAL_OK)
  {
    Error_Handler();
  }

  /** Enables the Clock Security System
  */
  HAL_RCC_EnableCSS();
}

/* MPU Configuration */

void MPU_Config(void)
{
  MPU_Region_InitTypeDef MPU_InitStruct = {0};

  /* Disables the MPU */
  HAL_MPU_Disable();

  /** Initializes and configures the Region and the memory to be protected
  */
  MPU_InitStruct.Enable = MPU_REGION_ENABLE;
  MPU_InitStruct.Number = MPU_REGION_NUMBER0;
  MPU_InitStruct.BaseAddress = 0x24000000;
  MPU_InitStruct.Size = MPU_REGION_SIZE_512KB;
  MPU_InitStruct.SubRegionDisable = 0x00;
  MPU_InitStruct.TypeExtField = MPU_TEX_LEVEL1;
  MPU_InitStruct.AccessPermission = MPU_REGION_FULL_ACCESS;
  MPU_InitStruct.DisableExec = MPU_INSTRUCTION_ACCESS_ENABLE;
  MPU_InitStruct.IsShareable = MPU_ACCESS_NOT_SHAREABLE;
  MPU_InitStruct.IsCacheable = MPU_ACCESS_CACHEABLE;
  MPU_InitStruct.IsBufferable = MPU_ACCESS_BUFFERABLE;

  HAL_MPU_ConfigRegion(&MPU_InitStruct);

  /** Initializes and configures the Region and the memory to be protected
  */
  MPU_InitStruct.Number = MPU_REGION_NUMBER1;
  MPU_InitStruct.BaseAddress = 0x30000000;
  MPU_InitStruct.Size = MPU_REGION_SIZE_128KB;
  MPU_InitStruct.TypeExtField = MPU_TEX_LEVEL0;
  MPU_InitStruct.IsBufferable = MPU_ACCESS_NOT_BUFFERABLE;

  HAL_MPU_ConfigRegion(&MPU_InitStruct);

  /** Initializes and configures the Region and the memory to be protected
  */
  MPU_InitStruct.Number = MPU_REGION_NUMBER2;
  MPU_InitStruct.BaseAddress = 0x30020000;

  HAL_MPU_ConfigRegion(&MPU_InitStruct);

  /** Initializes and configures the Region and the memory to be protected
  */
  MPU_InitStruct.Number = MPU_REGION_NUMBER3;
  MPU_InitStruct.BaseAddress = 0x30040000;
  MPU_InitStruct.Size = MPU_REGION_SIZE_32KB;

  HAL_MPU_ConfigRegion(&MPU_InitStruct);

  /** Initializes and configures the Region and the memory to be protected
  */
  MPU_InitStruct.Number = MPU_REGION_NUMBER4;
  MPU_InitStruct.BaseAddress = 0x38000000;
  MPU_InitStruct.Size = MPU_REGION_SIZE_64KB;

  HAL_MPU_ConfigRegion(&MPU_InitStruct);

  /** Initializes and configures the Region and the memory to be protected
  */
  MPU_InitStruct.Number = MPU_REGION_NUMBER5;
  MPU_InitStruct.BaseAddress = 0xD0000000;
  MPU_InitStruct.Size = MPU_REGION_SIZE_64MB;

  HAL_MPU_ConfigRegion(&MPU_InitStruct);

  /** Initializes and configures the Region and the memory to be protected
  */
  MPU_InitStruct.Number = MPU_REGION_NUMBER6;
  MPU_InitStruct.BaseAddress = 0x90000000;

  HAL_MPU_ConfigRegion(&MPU_InitStruct);
  /* Enables the MPU */
  HAL_MPU_Enable(MPU_PRIVILEGED_DEFAULT);

}

void HAL_TIM_PeriodElapsedCallback(TIM_HandleTypeDef *htim)
{
  if (htim->Instance == TIM6) {
    HAL_IncTick();
  }
}

void Error_Handler(void)
{
  __disable_irq();
  while (1)
  {
  }
}
